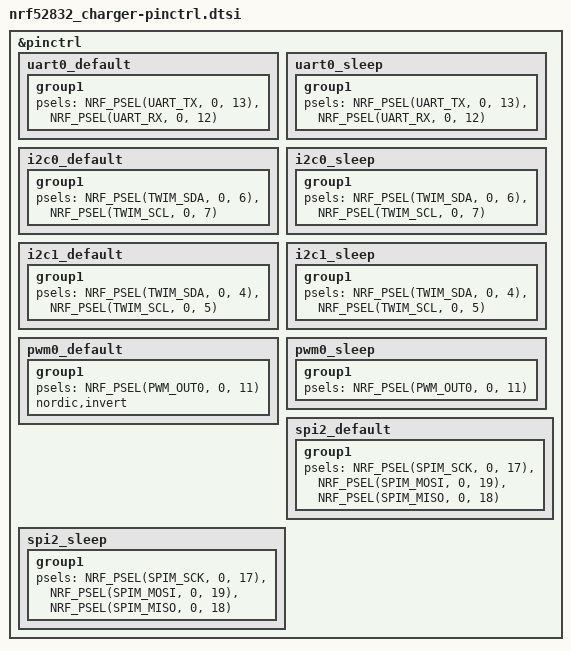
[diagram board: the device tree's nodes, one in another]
/*
 * Copyright (c) 2022 Nordic Semiconductor
 * SPDX-License-Identifier: Apache-2.0
 */

 &pinctrl {
	uart0_default: uart0_default {
		group1 {
			psels = <NRF_PSEL(UART_TX, 0, 13)>,
					<NRF_PSEL(UART_RX, 0, 12)>;
		};
	};

	uart0_sleep: uart0_sleep {
		group1 {
			psels = <NRF_PSEL(UART_TX, 0, 13)>,
					<NRF_PSEL(UART_RX, 0, 12)>;
		};
	};

	i2c0_default: i2c0_default {
		group1 {
			psels = <NRF_PSEL(TWIM_SDA, 0, 6)>,
				<NRF_PSEL(TWIM_SCL, 0, 7)>;
		};
	};

	i2c0_sleep: i2c0_sleep {
		group1 {
			psels = <NRF_PSEL(TWIM_SDA, 0, 6)>,
				<NRF_PSEL(TWIM_SCL, 0, 7)>;
		};
	};

	i2c1_default: i2c1_default {
		group1 {
			psels = <NRF_PSEL(TWIM_SDA, 0, 4)>,
				<NRF_PSEL(TWIM_SCL, 0, 5)>;
		};
	};

	i2c1_sleep: i2c1_sleep {
		group1 {
			psels = <NRF_PSEL(TWIM_SDA, 0, 4)>,
				<NRF_PSEL(TWIM_SCL, 0, 5)>;
		};
	};

	pwm0_default: pwm0_default {
		group1 {
			psels = <NRF_PSEL(PWM_OUT0, 0, 11)>;
			nordic,invert;
		};
	};

	pwm0_sleep: pwm0_sleep {
		group1 {
			psels = <NRF_PSEL(PWM_OUT0, 0, 11)>;
		};
	};
/* 
	spi0_default: spi0_default {
		group1 {
			psels = <NRF_PSEL(SPIM_SCK, 0, 17)>,
				<NRF_PSEL(SPIM_MOSI, 0, 19)>,
				<NRF_PSEL(SPIM_MISO, 0, 18)>;
		};
	};

	spi0_sleep: spi0_sleep {
		group1 {
			psels = <NRF_PSEL(SPIM_SCK, 0, 17)>,
				<NRF_PSEL(SPIM_MOSI, 0, 19)>,
				<NRF_PSEL(SPIM_MISO, 0, 18)>;
		};
	};

	spi1_default: spi1_default {
		group1 {
			psels = <NRF_PSEL(SPIM_SCK, 0, 17)>,
				<NRF_PSEL(SPIM_MOSI, 0, 19)>,
				<NRF_PSEL(SPIM_MISO, 0, 18)>;
		};
	};

	spi1_sleep: spi1_sleep {
		group1 {
			psels = <NRF_PSEL(SPIM_SCK, 0, 17)>,
				<NRF_PSEL(SPIM_MOSI, 0, 19)>,
				<NRF_PSEL(SPIM_MISO, 0, 18)>;
		};
	};
 */

	spi2_default: spi2_default {
		group1 {
			psels = <NRF_PSEL(SPIM_SCK, 0, 17)>,
				<NRF_PSEL(SPIM_MOSI, 0, 19)>,
				<NRF_PSEL(SPIM_MISO, 0, 18)>;
		};
	};

	spi2_sleep: spi2_sleep {
		group1 {
			psels = <NRF_PSEL(SPIM_SCK, 0, 17)>,
				<NRF_PSEL(SPIM_MOSI, 0, 19)>,
				<NRF_PSEL(SPIM_MISO, 0, 18)>;
		};
	};

};
